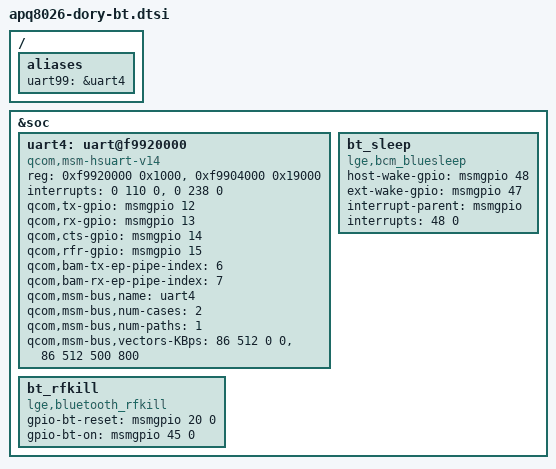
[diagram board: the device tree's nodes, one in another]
/* Copyright (c) 2012, Code Aurora Forum. All rights reserved.
 *
 * This program is free software; you can redistribute it and/or modify
 * it under the terms of the GNU General Public License version 2 and
 * only version 2 as published by the Free Software Foundation.
 *
 * This program is distributed in the hope that it will be useful,
 * but WITHOUT ANY WARRANTY; without even the implied warranty of
 * MERCHANTABILITY or FITNESS FOR A PARTICULAR PURPOSE.  See the
 * GNU General Public License for more details.
 */

/ {
	aliases {
		uart99 = &uart4;
	};
};

&soc {
	uart4: uart@f9920000 { //BLSP4
		compatible = "qcom,msm-hsuart-v14";
		status = "ok";
		reg = <0xf9920000 0x1000>,
			<0xf9904000 0x19000>;
		reg-names = "core_mem", "bam_mem";
		interrupts = <0 110 0>, <0 238 0>;
		interrupt-names = "core_irq", "bam_irq";

		qcom,tx-gpio = <&msmgpio 12 0x00>;
		qcom,rx-gpio = <&msmgpio 13 0x00>;
		qcom,cts-gpio = <&msmgpio 14 0x00>;
		qcom,rfr-gpio = <&msmgpio 15 0x00>;

		qcom,bam-tx-ep-pipe-index = <6>;
		qcom,bam-rx-ep-pipe-index = <7>;

		qcom,msm-bus,name = "uart4";
		qcom,msm-bus,num-cases = <2>;
		qcom,msm-bus,num-paths = <1>;
		qcom,msm-bus,vectors-KBps =
				<86 512 0 0>,
				<86 512 500 800>;
	};

	bt_rfkill {
		compatible = "lge,bluetooth_rfkill";
		gpio-bt-reset = <&msmgpio 20 0>;
		gpio-bt-on = <&msmgpio 45 0>;
	};


	/* To register BT wake-up devices for BT sleep */
	bt_sleep {
		compatible = "lge,bcm_bluesleep";
		host-wake-gpio = <&msmgpio 48 0>;
		ext-wake-gpio = <&msmgpio 47 0>;
		interrupt-parent = <&msmgpio>;
		interrupts = <48 0>;
		interrupt-names = "host_wake";
	};
};
